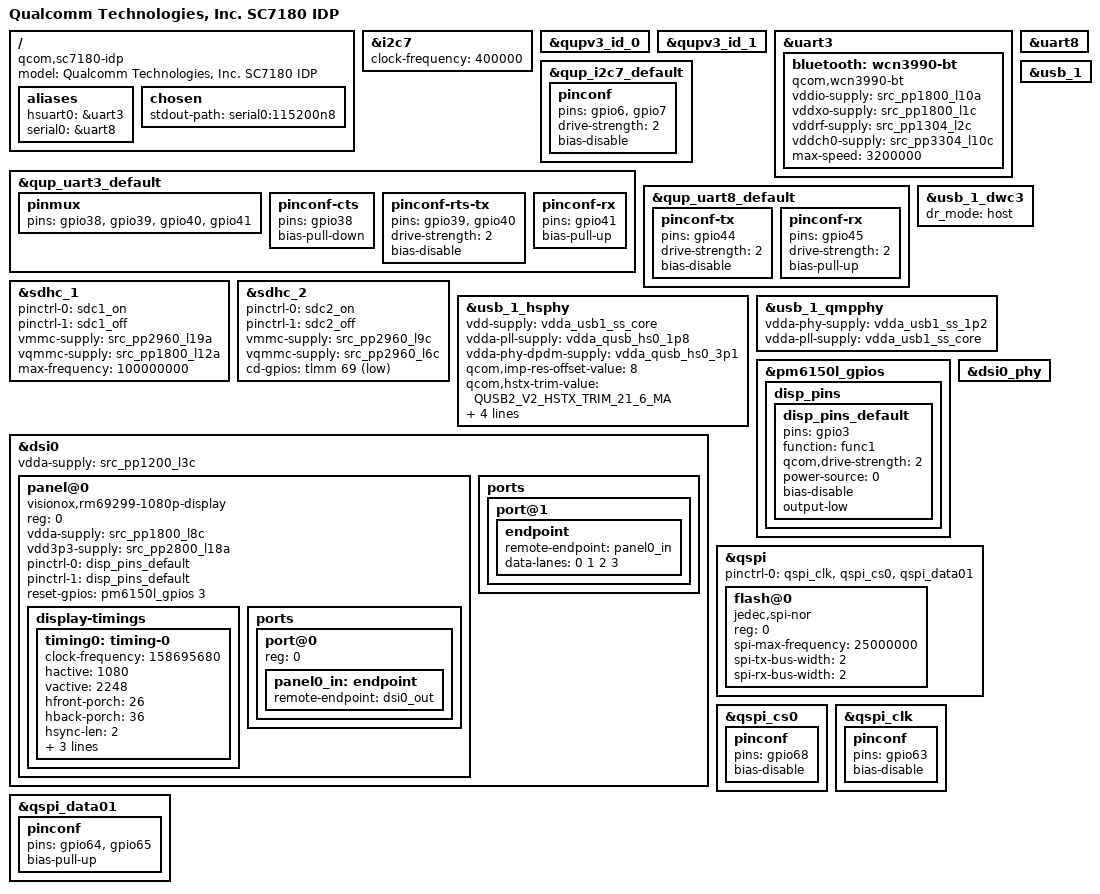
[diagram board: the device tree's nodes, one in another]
// SPDX-License-Identifier: GPL-2.0
/*
 * SC7180 IDP board device tree source
 *
 * Copyright (c) 2019, The Linux Foundation. All rights reserved.
 */

/dts-v1/;

#include <dt-bindings/gpio/gpio.h>
#include "sc7180.dtsi"

/ {
	model = "Qualcomm Technologies, Inc. SC7180 IDP";
	compatible = "qcom,sc7180-idp";

	aliases {
		hsuart0 = &uart3;
		serial0 = &uart8;
	};

	chosen {
		stdout-path = "serial0:115200n8";
	};
};

&i2c7 {
	status = "okay";
	clock-frequency = <400000>;
};

&qupv3_id_0 {
	status = "okay";
};

&qupv3_id_1 {
	status = "okay";
};

&uart3 {
	status = "okay";
	bluetooth: wcn3990-bt {
		compatible = "qcom,wcn3990-bt";
		vddio-supply = <&src_pp1800_l10a>;
		vddxo-supply = <&src_pp1800_l1c>;
		vddrf-supply = <&src_pp1304_l2c>;
		vddch0-supply = <&src_pp3304_l10c>;
		max-speed = <3200000>;
		status = "okay";
	};
};

&uart8 {
	status = "okay";
};

/* PINCTRL - additions to nodes defined in sc7180.dtsi */

&qup_i2c7_default {
	pinconf {
		pins = "gpio6", "gpio7";
		drive-strength = <2>;
		bias-disable;
	};
};

&qup_uart3_default {
	/* Change pinmux to all 4 pins since CTS and RTS are connected */
	pinmux {
		pins = "gpio38", "gpio39",
		       "gpio40", "gpio41";
	};

	pinconf-cts {
		/*
		 * Configure a pull-down on 38 (CTS) to match the pull of
		 * the Bluetooth module.
		 */
		pins = "gpio38";
		bias-pull-down;
	};

	pinconf-rts-tx {
		/* We'll drive 39 (RTS) and 40 (TX), so no pull */
		pins = "gpio39", "gpio40";
		drive-strength = <2>;
		bias-disable;
	};

	pinconf-rx {
		/*
		 * Configure a pull-up on 41 (RX). This is needed to avoid
		 * garbage data when the TX pin of the Bluetooth module is
		 * in tri-state (module powered off or not driving the
		 * signal yet).
		 */
		pins = "gpio41";
		bias-pull-up;
	};
};

&qup_uart8_default {
	pinconf-tx {
		pins = "gpio44";
		drive-strength = <2>;
		bias-disable;
	};

	pinconf-rx {
		pins = "gpio45";
		drive-strength = <2>;
		bias-pull-up;
	};
};

&sdhc_1 {
	status = "ok";

	pinctrl-names = "default", "sleep";
	pinctrl-0 = <&sdc1_on>;
	pinctrl-1 = <&sdc1_off>;
	vmmc-supply = <&src_pp2960_l19a>;
	vqmmc-supply = <&src_pp1800_l12a>;

	max-frequency = <100000000>;

	/delete-property/ mmc-hs200-1_8v;
	/delete-property/ mmc-hs400-1_8v;
	/delete-property/ mmc-hs400-enhanced-strobe;
};

&sdhc_2 {
	status = "ok";

	pinctrl-names = "default","sleep";
	pinctrl-0 = <&sdc2_on>;
	pinctrl-1 = <&sdc2_off>;
	vmmc-supply  = <&src_pp2960_l9c>;
	vqmmc-supply = <&src_pp2960_l6c>;

	cd-gpios = <&tlmm 69 GPIO_ACTIVE_LOW>;
};

&usb_1 {
	status = "okay";
};

&usb_1_dwc3 {
	dr_mode = "host";
};

&usb_1_hsphy {
	status = "okay";
	vdd-supply = <&vdda_usb1_ss_core>;
	vdda-pll-supply = <&vdda_qusb_hs0_1p8>;
	vdda-phy-dpdm-supply = <&vdda_qusb_hs0_3p1>;
	qcom,imp-res-offset-value = <8>;
	qcom,hstx-trim-value = <QUSB2_V2_HSTX_TRIM_21_6_MA>;
	qcom,preemphasis-level = <QUSB2_V2_PREEMPHASIS_5_PERCENT>;
	qcom,preemphasis-width = <QUSB2_V2_PREEMPHASIS_WIDTH_HALF_BIT>;
};

&usb_1_qmpphy {
	status = "okay";
	vdda-phy-supply = <&vdda_usb1_ss_1p2>;
	vdda-pll-supply = <&vdda_usb1_ss_core>;
};
&pm6150l_gpios {
	disp_pins {
		disp_pins_default: disp_pins_default{
			pins = "gpio3";
			function = "func1";
			qcom,drive-strength = <2>;
			power-source = <0>;
			bias-disable;
			output-low;
		};
	};
};

&dsi0 {
	status = "okay";

	vdda-supply = <&src_pp1200_l3c>;

	panel@0 {
		compatible = "visionox,rm69299-1080p-display";
		reg = <0>;

		vdda-supply = <&src_pp1800_l8c>;
		vdd3p3-supply = <&src_pp2800_l18a>;

		pinctrl-names = "default", "suspend";
		pinctrl-0 = <&disp_pins_default>;
		pinctrl-1 = <&disp_pins_default>;

		reset-gpios = <&pm6150l_gpios 3 0>;

		display-timings {
			timing0: timing-0 {
				/* originally
				 * 268316160 Mhz,
				 * but value below fits
				 * better w/ downstream
				 */
				clock-frequency = <158695680>;
				hactive = <1080>;
				vactive = <2248>;
				hfront-porch = <26>;
				hback-porch = <36>;
				hsync-len = <2>;
				vfront-porch = <56>;
				vback-porch = <4>;
				vsync-len = <4>;
			};
		};

		ports {
			#address-cells = <1>;
			#size-cells = <0>;
			port@0 {
				reg = <0>;
				panel0_in: endpoint {
					remote-endpoint = <&dsi0_out>;
				};
			};
		};
	};

	ports {
		port@1 {
			endpoint {
				remote-endpoint = <&panel0_in>;
				data-lanes = <0 1 2 3>;
			};
		};
	};
};

&dsi0_phy {
	status = "okay";
};

&qspi {
	status = "okay";
	pinctrl-names = "default";
	pinctrl-0 = <&qspi_clk &qspi_cs0 &qspi_data01>;

	flash@0 {
		compatible = "jedec,spi-nor";
		reg = <0>;

		/*
		 * In theory chip supports up to 104 MHz and controller up
		 * to 80 MHz, but above 25 MHz wasn't reliable so we'll use
		 * that for now.  b:117440651
		 */
		spi-max-frequency = <25000000>;
		spi-tx-bus-width = <2>;
		spi-rx-bus-width = <2>;
	};
};

/* PINCTRL - additions to nodes defined in sc7180.dtsi */

&qspi_cs0 {
		pinconf {
			pins = "gpio68";
			bias-disable;
		};
};

&qspi_clk {
		pinconf {
			pins = "gpio63";
			bias-disable;
		};
};

&qspi_data01 {
		pinconf {
			pins = "gpio64", "gpio65";

			/* High-Z when no transfers; nice to park the lines */
			bias-pull-up;
		};
};
